# SAM9X60 device description
Architecture: ARM926EJS; Family: SAM9; Series: SAM9X
Registers are 32-bit, read-write, no defined reset value unless marked. A register's access mark holds for its fields unless they carry their own. Offsets are from the block's base; [hi:lo] are bit positions; lines under a group give offsets from that group; {n}, {i} and the like mark numbered series; 'fields as' and 'values as' point back to an identical list.

## PWM — Pulse Width Modulation Controller
Instances: PWM 0xF8034000
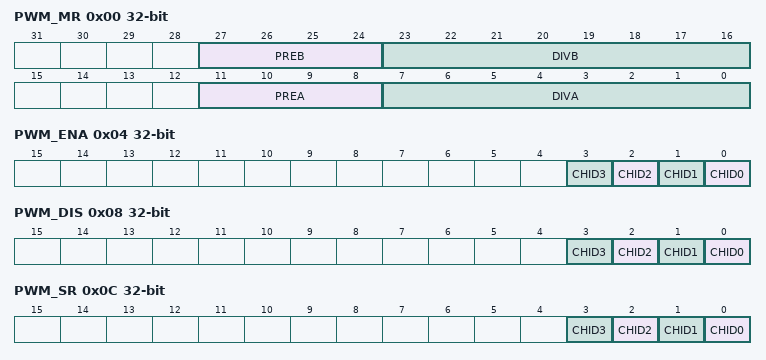
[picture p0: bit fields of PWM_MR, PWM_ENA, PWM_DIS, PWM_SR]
0x00 PWM_MR — PWM Mode Register
  [27:24] PREB — CLKB Source Clock Selection
    0=MCK (Master Clock); 1=MCKDIV2 (Master Clock divided by 2); 2=MCKDIV4 (Master Clock divided by 4); 3=MCKDIV8 (Master Clock divided by 8); 4=MCKDIV16 (Master Clock divided by 16); 5=MCKDIV32 (Master Clock divided by 32); 6=MCKDIV64 (Master Clock divided by 64); 7=MCKDIV128 (Master Clock divided by 128); 8=MCKDIV256 (Master Clock divided by 256); 9=MCKDIV512 (Master Clock divided by 512); 10=MCKDIV1024 (Master Clock divided by 1024)
  [23:16] DIVB — CLKB Divide Factor
    0=CLK_OFF (CLKB clock is turned off); 1=CLK_DIV1 (CLKB clock is clock selected by PREB)
  [11:8] PREA — CLKA Source Clock Selection
    values as PREB
  [7:0] DIVA — CLKA Divide Factor
    0=CLK_OFF (CLKA clock is turned off); 1=CLK_DIV1 (CLKA clock is clock selected by PREA)
0x04 PWM_ENA wo — PWM Enable Register
  [n] CHID{n} (n=0..3) — Channel ID
0x08 PWM_DIS wo — PWM Disable Register
  [n] CHID{n} (n=0..3) — Channel ID
0x0C PWM_SR ro — PWM Status Register
  [n] CHID{n} (n=0..3) — Channel ID
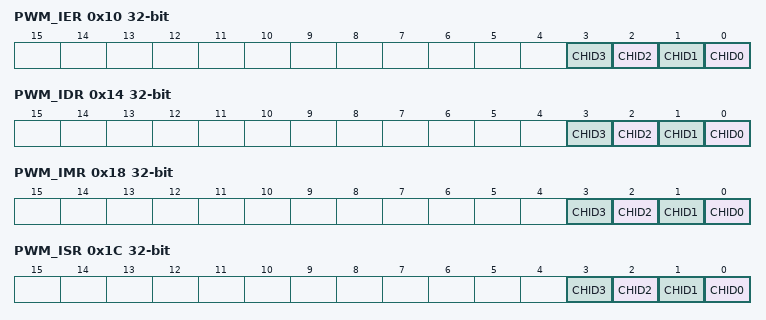
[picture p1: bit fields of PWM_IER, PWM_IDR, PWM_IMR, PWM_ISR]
0x10 PWM_IER wo — PWM Interrupt Enable Register
  [n] CHID{n} (n=0..3) — Channel ID
0x14 PWM_IDR wo — PWM Interrupt Disable Register
  [n] CHID{n} (n=0..3) — Channel ID
0x18 PWM_IMR ro — PWM Interrupt Mask Register
  [n] CHID{n} (n=0..3) — Channel ID
0x1C PWM_ISR ro — PWM Interrupt Status Register
  [n] CHID{n} (n=0..3) — Channel ID
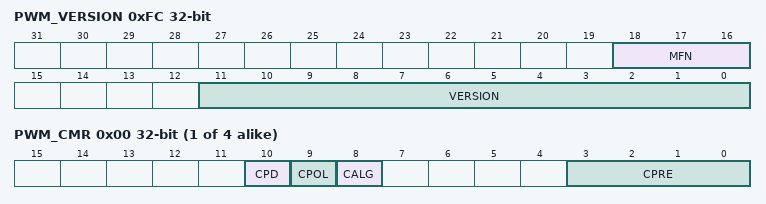
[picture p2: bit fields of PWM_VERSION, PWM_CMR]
0xFC PWM_VERSION ro — Version Register
  [18:16] MFN — Metal Fix Number
  [11:0] VERSION — Version of the Hardware Module
{0x200+0x20*i} PWM_CH_NUM[{i}] (i=0..3) group
  0x00 PWM_CMR — PWM Channel Mode Register
    [10] CPD — Channel Update Period
    [9] CPOL — Channel Polarity
    [8] CALG — Channel Alignment
    [3:0] CPRE — Channel Prescaler
      0=MCK (Master Clock); 1=MCKDIV2 (Master Clock divided by 2); 2=MCKDIV4 (Master Clock divided by 4); 3=MCKDIV8 (Master Clock divided by 8); 4=MCKDIV16 (Master Clock divided by 16); 5=MCKDIV32 (Master Clock divided by 32); 6=MCKDIV64 (Master Clock divided by 64); 7=MCKDIV128 (Master Clock divided by 128); 8=MCKDIV256 (Master Clock divided by 256); 9=MCKDIV512 (Master Clock divided by 512); 10=MCKDIV1024 (Master Clock divided by 1024); 11=CLKA (Clock A); 12=CLKB (Clock B)
  0x04 PWM_CDTY — PWM Channel Duty Cycle Register
    [31:0] CDTY — Channel Duty Cycle
  0x08 PWM_CPRD — PWM Channel Period Register
    [31:0] CPRD — Channel Period
  0x0C PWM_CCNT ro — PWM Channel Counter Register
    [31:0] CNT — Channel Counter Register
  0x10 PWM_CUPD wo — PWM Channel Update Register
    [31:0] CUPD — Channel Update Register

## RSTC — Reset Controller
Instances: RSTC 0xFFFFFE00
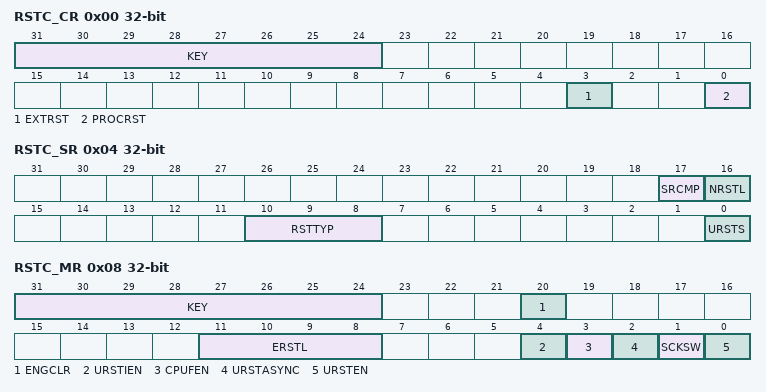
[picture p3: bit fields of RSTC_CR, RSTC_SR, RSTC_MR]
0x00 RSTC_CR wo — Control Register
  [31:24] KEY — System Reset Key
    165=PASSWD (Writing any other value in this field aborts the write operation.)
  [3] EXTRST — External Reset
  [0] PROCRST — Processor Reset
0x04 RSTC_SR ro — Status Register
  [17] SRCMP — Software Reset Command in Progress
  [16] NRSTL — NRST Pin Level
  [10:8] RSTTYP — Reset Type
    0=GENERAL_RST (First powerup reset); 1=BACKUP_RST (Return from Backup mode); 2=WDT_RST (Watchdog fault occurred); 3=SOFT_RST (Processor reset required by the software); 4=USER_RST (NRST pin detected low); 6=CPU_FAIL_RST (CPU clock failure detection occurred); 7=SLCK_XTAL_RST (32.768 kHz crystal failure detection fault occurred)
  [0] URSTS — User Reset Status
0x08 RSTC_MR — Mode Register
  [31:24] KEY — Write Access Password
    165=PASSWD (Writing any other value in this field aborts the write operation. Always reads as 0.)
  [20] ENGCLR — Enable GPBR Clear on Tamper Event
  [11:8] ERSTL — External Reset Length
  [4] URSTIEN — User Reset Interrupt Enable
  [3] CPUFEN — CPU Fail Enable
  [2] URSTASYNC — User Reset Asynchronous Control
  [1] SCKSW — Slow Clock Switching
  [0] URSTEN — User Reset Enable
